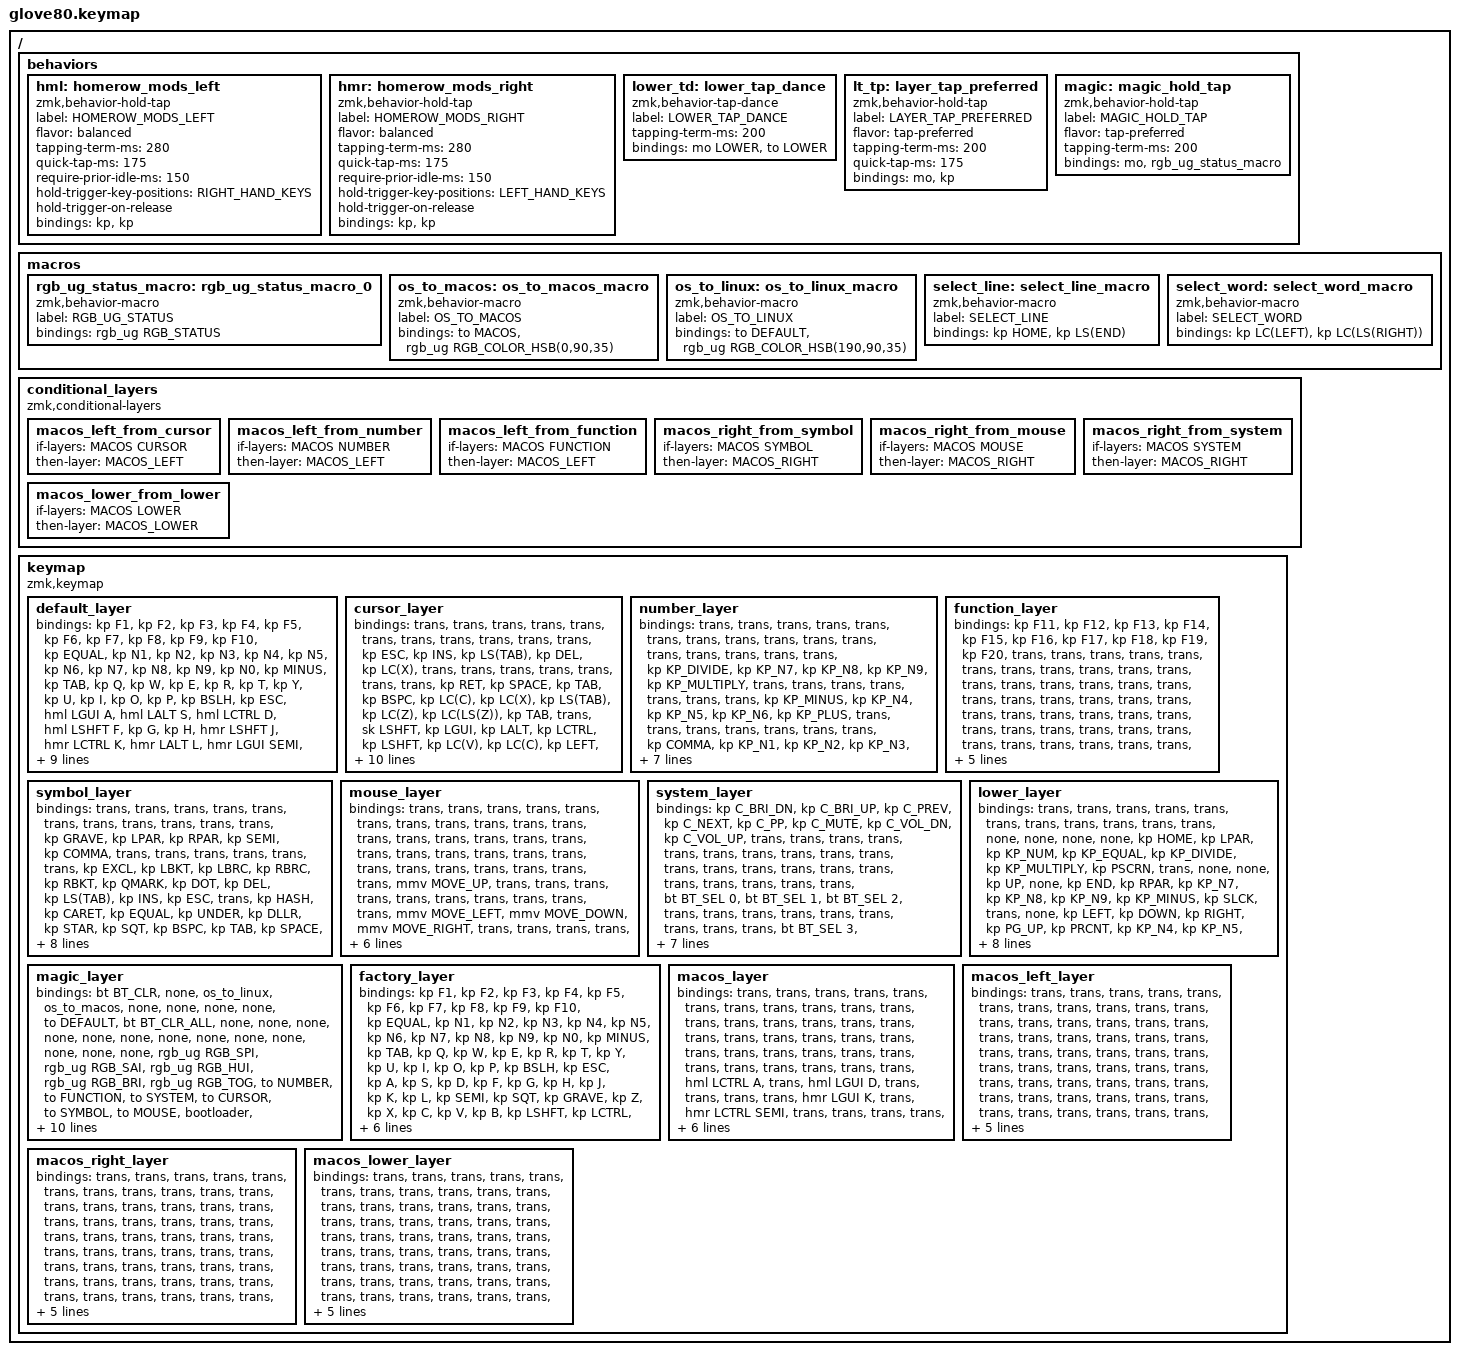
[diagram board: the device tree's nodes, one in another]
/*
 * Dual-OS (macOS / Linux) Glove80 keymap
 *
 * Layout, home-row-mod, and bilateral-combination ideas adapted from
 * sunaku/glove80-keymaps (https://github.com/sunaku/glove80-keymaps).
 * See ../README.md for the full design writeup.
 *
 * Copyright (c) 2020 The ZMK Contributors
 * SPDX-License-Identifier: MIT
 */

#include <behaviors.dtsi>
#include <dt-bindings/zmk/keys.h>
#include <dt-bindings/zmk/bt.h>
#include <dt-bindings/zmk/ext_power.h>
#include <dt-bindings/zmk/outputs.h>
#include <dt-bindings/zmk/rgb.h>
#include <dt-bindings/zmk/pointing.h>

#define HYPER LC(LS(LG(LALT)))

// ---------------------------------------------------------------------------
// Layers
// ---------------------------------------------------------------------------
#define DEFAULT      0
#define CURSOR       1
#define NUMBER       2
#define FUNCTION     3
#define SYMBOL       4
#define MOUSE        5
#define SYSTEM       6
#define LOWER        7
#define MAGIC        8
#define FACTORY      9
#define MACOS        10
#define MACOS_LEFT   11
#define MACOS_RIGHT  12
#define MACOS_LOWER  13

// ---------------------------------------------------------------------------
// Bilateral-combination key-position groups.
//
// Glove80 numbers its 80 key positions 0-79 in physical row-major order (see
// README.md "Bilateral combinations" for the full diagram). LEFT_HAND_KEYS /
// RIGHT_HAND_KEYS list every position that physically belongs to that hand
// (including its own thumb keys). Home-row-mod hold-taps use the *opposite*
// hand's list as `hold-trigger-key-positions`, so a mod only resolves as a
// HOLD when the very next key pressed is on the other hand -- same-hand fast
// typing always resolves as a plain TAP instead of misfiring a modifier.
// ---------------------------------------------------------------------------
#define LEFT_HAND_KEYS \
     0  1  2  3  4 10 11 12 13 14 15 22 23 24 25 26 27 34 35 36 37 38 39 \
    46 47 48 49 50 51 52 53 54 64 65 66 67 68 69 70 71

#define RIGHT_HAND_KEYS \
     5  6  7  8  9 16 17 18 19 20 21 28 29 30 31 32 33 40 41 42 43 44 45 \
    55 56 57 58 59 60 61 62 63 72 73 74 75 76 77 78 79

/ {
    behaviors {
        // Bilateral-combination home row mods. GACS order (pinky->index):
        // GUI, ALT, CTRL, SHIFT. See macOS overlay below for the OS-specific
        // pinky<->middle (GUI<->CTRL) swap.
        hml: homerow_mods_left {
            compatible = "zmk,behavior-hold-tap";
            label = "HOMEROW_MODS_LEFT";
            #binding-cells = <2>;
            flavor = "balanced";
            tapping-term-ms = <280>;
            quick-tap-ms = <175>;
            require-prior-idle-ms = <150>;
            hold-trigger-key-positions = <RIGHT_HAND_KEYS>;
            hold-trigger-on-release;
            bindings = <&kp>, <&kp>;
        };

        hmr: homerow_mods_right {
            compatible = "zmk,behavior-hold-tap";
            label = "HOMEROW_MODS_RIGHT";
            #binding-cells = <2>;
            flavor = "balanced";
            tapping-term-ms = <280>;
            quick-tap-ms = <175>;
            require-prior-idle-ms = <150>;
            hold-trigger-key-positions = <LEFT_HAND_KEYS>;
            hold-trigger-on-release;
            bindings = <&kp>, <&kp>;
        };

        // Tap = momentary Lower, double-tap = stay on Lower until tapped again.
        lower_td: lower_tap_dance {
            compatible = "zmk,behavior-tap-dance";
            label = "LOWER_TAP_DANCE";
            #binding-cells = <0>;
            tapping-term-ms = <200>;
            bindings = <&mo LOWER>, <&to LOWER>;
        };

        // TailorKey-style layer-tap: tap = the key's normal keycode, hold =
        // a layer. "tap-preferred" resolves as a tap the instant another key
        // is pressed, so fast typing/rolling through Space/Backspace/Enter
        // never misfires a layer -- only a deliberate solo hold does. This
        // is how TailorKey (https://sites.google.com/view/tailorkey/moergo/glove80)
        // reaches Symbol/Cursor/Mouse: hold Space/Backspace/Enter instead of
        // spending dedicated thumb keys on them.
        lt_tp: layer_tap_preferred {
            compatible = "zmk,behavior-hold-tap";
            label = "LAYER_TAP_PREFERRED";
            #binding-cells = <2>;
            flavor = "tap-preferred";
            tapping-term-ms = <200>;
            quick-tap-ms = <175>;
            bindings = <&mo>, <&kp>;
        };

        // Hold = momentary Magic layer, tap = show RGB/battery status (stock MoErgo behavior).
        magic: magic_hold_tap {
            compatible = "zmk,behavior-hold-tap";
            label = "MAGIC_HOLD_TAP";
            #binding-cells = <2>;
            flavor = "tap-preferred";
            tapping-term-ms = <200>;
            bindings = <&mo>, <&rgb_ug_status_macro>;
        };
    };

    macros {
        rgb_ug_status_macro: rgb_ug_status_macro_0 {
            label = "RGB_UG_STATUS";
            compatible = "zmk,behavior-macro";
            #binding-cells = <0>;
            bindings = <&rgb_ug RGB_STATUS>;
        };

        // OS-mode select. Each key unconditionally sets the OS overlay layer
        // state AND recolors the underglow, so the two keys behave like a
        // radio button (not a toggle) and the RGB always matches the mode.
        os_to_macos: os_to_macos_macro {
            label = "OS_TO_MACOS";
            compatible = "zmk,behavior-macro";
            #binding-cells = <0>;
            bindings
                = <&to MACOS>,
                  <&rgb_ug RGB_COLOR_HSB(0,90,35)>;
        };

        os_to_linux: os_to_linux_macro {
            label = "OS_TO_LINUX";
            compatible = "zmk,behavior-macro";
            #binding-cells = <0>;
            bindings
                = <&to DEFAULT>,
                  <&rgb_ug RGB_COLOR_HSB(190,90,35)>;
        };

        // Select from line start to line end -- ZMK has no built-in
        // "select line", Sunaku's Cursor layer expects one.
        select_line: select_line_macro {
            label = "SELECT_LINE";
            compatible = "zmk,behavior-macro";
            #binding-cells = <0>;
            bindings = <&kp HOME>, <&kp LS(END)>;
        };

        // Jump to the start of the current word, then select to its end --
        // Sunaku's Cursor layer's "select word".
        select_word: select_word_macro {
            label = "SELECT_WORD";
            compatible = "zmk,behavior-macro";
            #binding-cells = <0>;
            bindings = <&kp LC(LEFT)>, <&kp LC(LS(RIGHT))>;
        };
    };

    // ZMK cannot detect the connected host's OS -- there is no such signal
    // over USB/BLE. The MACOS layer above is a persistent overlay toggled
    // explicitly by the os_to_macos/os_to_linux keys on the Magic layer.
    // conditional-layers combines it with whichever functional layer (Cursor/
    // Number/Function on the left, Symbol/Mouse/System on the right, or
    // Lower) is currently held, activating the matching *_left/_right/_lower
    // overlay so Mac-specific bindings on those layers take effect too.
    conditional_layers {
        compatible = "zmk,conditional-layers";
        macos_left_from_cursor   { if-layers = <MACOS CURSOR>;   then-layer = <MACOS_LEFT>; };
        macos_left_from_number   { if-layers = <MACOS NUMBER>;   then-layer = <MACOS_LEFT>; };
        macos_left_from_function { if-layers = <MACOS FUNCTION>; then-layer = <MACOS_LEFT>; };
        macos_right_from_symbol  { if-layers = <MACOS SYMBOL>;   then-layer = <MACOS_RIGHT>; };
        macos_right_from_mouse   { if-layers = <MACOS MOUSE>;    then-layer = <MACOS_RIGHT>; };
        macos_right_from_system  { if-layers = <MACOS SYSTEM>;   then-layer = <MACOS_RIGHT>; };
        macos_lower_from_lower   { if-layers = <MACOS LOWER>;    then-layer = <MACOS_LOWER>; };
    };

    keymap {
        compatible = "zmk,keymap";

        // -----------------------------------------------------------------------------------------------------------------------------
        // |  F1   |  F2 |  F3 |  F4  |  F5  |                                                               |  F6   |  F7   |  F8  |   F9  |  F10 |
        // |  =    |  1  |  2  |  3   |  4   |  5   |                                                 |  6   |   7   |   8   |  9   |   0   |   -  |
        // |  TAB  |  Q  |  W  |  E   |  R   |  T   |                                                 |  Y   |   U   |   I   |  O   |   P   |   \  |
        // |  ESC  | GUI/A|ALT/S|CTRL/D|SHFT/F|  G   |                                                 |  H   |SHFT/J |CTRL/K |ALT/L |GUI/;  |   '  |
        // |   `   |  Z  |  X  |  C   |  V   |  B   |NUMBER |CAPSWORD|LOWERtd| |CAPS  |  --  |SYSTEM |  N   |   M   |   ,   |  .   |   /   | PGUP |
        // |MAGIC/RGB|HOME| END | LEFT|RIGHT |      |BSPC/CURSOR|DEL|FUNCTION| |MAGIC |RET/MOUSE|SPACE/SYMBOL| |  UP   | DOWN  |  [   |   ]   | PGDN |
        //
        // TailorKey-style layer access: Cursor/Mouse/Symbol have no dedicated
        // thumb key -- hold Backspace/Enter/Space instead (see lt_tp above).
        // That frees three thumb keys for Caps Word and Caps Lock (`--` is a
        // spare, currently &none).
        default_layer {
            bindings = <
        &kp F1       &kp F2       &kp F3      &kp F4      &kp F5                                                                          &kp F6  &kp F7      &kp F8      &kp F9      &kp F10
        &kp EQUAL    &kp N1       &kp N2      &kp N3      &kp N4      &kp N5                                                        &kp N6  &kp N7  &kp N8      &kp N9      &kp N0      &kp MINUS
        &kp TAB      &kp Q        &kp W       &kp E       &kp R       &kp T                                                         &kp Y   &kp U   &kp I       &kp O       &kp P       &kp BSLH
        &kp ESC      &hml LGUI A  &hml LALT S &hml LCTRL D &hml LSHFT F &kp G                                                        &kp H   &hmr LSHFT J &hmr LCTRL K &hmr LALT L &hmr LGUI SEMI &kp SQT
        &kp GRAVE    &kp Z        &kp X       &kp C       &kp V       &kp B    &mo NUMBER &caps_word &lower_td   &kp CAPS &none &mo SYSTEM  &kp N   &kp M   &kp COMMA   &kp DOT     &kp FSLH    &kp PG_UP
        &magic MAGIC 0 &kp HOME   &kp END     &kp LEFT    &kp RIGHT           &lt_tp CURSOR BSPC   &kp DEL    &mo FUNCTION &mo MAGIC &lt_tp MOUSE RET   &lt_tp SYMBOL SPACE           &kp UP  &kp DOWN    &kp LBKT    &kp RBKT    &kp PG_DN
            >;
        };

        // Sunaku's actual Cursor layer (https://sunaku.github.io/moergo-glove80-keyboard.html#cursor-layer),
        // which TailorKey's own Cursor layer is explicitly built on -- same
        // physical row/column mapping approach as Symbol above. Cut/Copy/
        // Paste/Undo/Redo/Find are plain Ctrl-chords here (portable across
        // OSes); see macos_right_layer below for the one Mac-specific
        // override Sunaku's diagram calls for (Home/End -> Cmd+Left/Right).
        // Left thumb cluster stays &trans -- Sunaku's own left thumb is idle
        // there too (his Cursor activation is a dedicated left-hand key,
        // same physical role as our held Backspace, and he leaves the rest
        // of that cluster grey). Right thumb cluster gets his selection
        // shortcuts (Extend word/line, Select none/word/line/all) since his
        // diagram populates all six positions there, including the one that
        // doubles as this file's secondary `&mo MAGIC` key -- fine here
        // since the primary Magic key (bottom-left corner, held via
        // `&magic`) stays &trans and reachable throughout. One Sunaku cell
        // (left R6/outermost, "Search bar") was dropped rather than
        // overriding *that* Magic key.
        cursor_layer {
            bindings = <
        &trans       &trans       &trans       &trans       &trans       &trans       &trans       &trans       &trans       &trans
        &trans       &kp ESC      &kp INS      &kp LS(TAB)  &kp DEL      &kp LC(X)                                                    &trans       &trans       &trans       &trans       &trans       &trans
        &trans       &kp RET      &kp SPACE    &kp TAB      &kp BSPC     &kp LC(C)                                                    &kp LC(X)    &kp LS(TAB)  &kp LC(Z)    &kp LC(LS(Z)) &kp TAB     &trans
        &sk LSHFT    &kp LGUI     &kp LALT     &kp LCTRL    &kp LSHFT    &kp LC(V)                                                    &kp LC(C)    &kp LEFT     &kp UP       &kp DOWN     &kp RIGHT    &sk RSHFT
        &kp LC(L)    &kp LC(A)    &select_line &select_word &kp LC(F)   &trans        &trans       &trans       &trans       &kp RIGHT    &kp LS(END)  &kp LC(LS(RIGHT)) &kp LC(V) &kp HOME     &kp PG_UP    &kp PG_DN    &kp END      &kp LC(L)
        &trans       &kp LC(Z)    &kp LC(LS(Z)) &kp LS(F3)  &kp F3                   &trans       &trans       &trans       &kp LC(A)    &select_line &select_word              &kp LC(F)    &kp LS(F3)   &kp F3       &kp LC(H)    &kp LC(K)
            >;
        };

        number_layer {
            bindings = <
        &trans       &trans       &trans       &trans       &trans       &trans       &trans       &trans       &trans       &trans
        &trans       &trans       &trans       &trans       &trans       &trans       &kp KP_DIVIDE &kp KP_N7   &kp KP_N8    &kp KP_N9    &kp KP_MULTIPLY &trans
        &trans       &trans       &trans       &trans       &trans       &trans       &kp KP_MINUS &kp KP_N4    &kp KP_N5    &kp KP_N6    &kp KP_PLUS  &trans
        &trans       &trans       &trans       &trans       &trans       &trans       &kp COMMA    &kp KP_N1    &kp KP_N2    &kp KP_N3    &kp KP_EQUAL &trans
        &trans       &trans       &trans       &trans       &trans       &trans       &trans       &trans       &trans       &trans       &trans       &trans       &kp DOT      &kp KP_N0    &kp KP_N0    &kp KP_DOT   &kp KP_ENTER &trans
        &trans       &trans       &trans       &trans       &trans       &trans       &trans       &trans       &trans       &trans       &trans       &trans       &trans       &trans       &trans       &trans
            >;
        };

        function_layer {
            bindings = <
        &kp F11      &kp F12      &kp F13      &kp F14      &kp F15      &kp F16      &kp F17      &kp F18      &kp F19      &kp F20
        &trans       &trans       &trans       &trans       &trans       &trans       &trans       &trans       &trans       &trans       &trans       &trans
        &trans       &trans       &trans       &trans       &trans       &trans       &trans       &trans       &trans       &trans       &trans       &trans
        &trans       &trans       &trans       &trans       &trans       &trans       &trans       &trans       &trans       &trans       &trans       &trans
        &trans       &trans       &trans       &trans       &trans       &trans       &trans       &trans       &trans       &trans       &trans       &trans       &trans       &trans       &trans       &trans       &trans       &trans
        &trans       &trans       &trans       &trans       &trans       &trans       &trans       &trans       &trans       &trans       &trans       &trans       &trans       &trans       &trans       &trans
            >;
        };

        // Sunaku's actual Symbol layer (https://sunaku.github.io/moergo-glove80-keyboard.html#symbol-layer),
        // which TailorKey's own Symbol layer is explicitly built on. Mapped
        // by physical row/column onto this file's layout, not by borrowed
        // semantics -- e.g. row4 is wherever the home row lives here, not
        // "wherever Sunaku's A/S/D/F happen to sit". Right-hand row3/row4
        // also carry Sunaku's "spacegram" fix: Space itself is busy being
        // held to reach this layer, so Space/Backspace/Tab/Enter/Del/Insert
        // get plain-tap duplicates on the home row so you don't have to let
        // go of Space to use them. Left thumb cluster gets Sunaku's extra
        // symbols too (| . * % : @) -- his Symbol activation is a dedicated
        // key, same as ours (Space), so his left thumb is just as idle as
        // ours while Symbol is held, and he repurposes it. Right thumb
        // cluster stays &trans (Sunaku's diagram leaves his idle too, aside
        // from the activation key itself).
        // Two Sunaku cells were dropped as ambiguous rather than guessed at:
        // a two-dot glyph (left R6/outermost) and a triple-grave glyph
        // (right R4/outermost, both currently &trans / pass-through).
        symbol_layer {
            bindings = <
        &trans       &trans       &trans       &trans       &trans       &trans       &trans       &trans       &trans       &trans
        &trans       &kp GRAVE    &kp LPAR     &kp RPAR     &kp SEMI     &kp COMMA                                                    &trans       &trans       &trans       &trans       &trans       &trans
        &kp EXCL     &kp LBKT     &kp LBRC     &kp RBRC     &kp RBKT     &kp QMARK                                                    &kp DOT      &kp DEL      &kp LS(TAB)  &kp INS      &kp ESC      &trans
        &kp HASH     &kp CARET    &kp EQUAL    &kp UNDER    &kp DLLR     &kp STAR                                                     &kp SQT      &kp BSPC     &kp TAB      &kp SPACE    &kp RET      &trans
        &kp TILDE    &kp LT       &kp PIPE     &kp MINUS    &kp GT       &kp FSLH     &kp PIPE     &kp DOT      &kp STAR     &trans       &trans       &trans       &kp SEMI     &kp DQT      &kp SQT      &kp GRAVE    &kp BSLH     &sk RSHFT
        &trans       &kp AMPS     &kp SQT      &kp DQT      &kp PLUS                 &kp PRCNT    &kp COLON    &kp AT       &trans       &trans       &trans                    &kp LSHFT    &kp LCTRL    &kp LALT     &kp LGUI     &trans
            >;
        };

        mouse_layer {
            bindings = <
        &trans       &trans       &trans       &trans       &trans       &trans       &trans       &trans       &trans       &trans
        &trans       &trans       &trans       &trans       &trans       &trans       &trans       &trans       &trans       &trans       &trans       &trans
        &trans       &trans       &trans       &trans       &trans       &trans       &trans       &trans       &mmv MOVE_UP &trans       &trans       &trans
        &trans       &trans       &trans       &trans       &trans       &trans       &trans       &mmv MOVE_LEFT &mmv MOVE_DOWN &mmv MOVE_RIGHT &trans &trans
        &trans       &trans       &trans       &trans       &trans       &trans       &trans       &trans       &trans       &mkp LCLK    &mkp MCLK    &mkp RCLK    &msc SCRL_UP &trans       &trans       &trans       &trans       &trans
        &trans       &trans       &trans       &trans       &trans       &trans       &trans       &trans       &trans       &trans       &trans       &msc SCRL_DOWN &trans     &trans       &trans       &trans
            >;
        };

        system_layer {
            bindings = <
        &kp C_BRI_DN &kp C_BRI_UP &kp C_PREV   &kp C_NEXT   &kp C_PP     &kp C_MUTE   &kp C_VOL_DN &kp C_VOL_UP &trans       &trans
        &trans       &trans       &trans       &trans       &trans       &trans       &trans       &trans       &trans       &trans       &trans       &trans
        &trans       &trans       &trans       &trans       &trans       &trans       &trans       &bt BT_SEL 0 &bt BT_SEL 1 &bt BT_SEL 2 &trans       &trans
        &trans       &trans       &trans       &trans       &trans       &trans       &trans       &bt BT_SEL 3 &bt BT_SEL 4 &out OUT_USB &trans       &trans
        &trans       &trans       &trans       &trans       &trans       &trans       &trans       &trans       &trans       &trans       &trans       &trans       &trans       &out OUT_BLE &out OUT_TOG &trans       &trans       &trans
        &trans       &trans       &trans       &trans       &trans       &trans       &trans       &trans       &trans       &trans       &trans       &trans       &trans       &trans       &trans       &trans
            >;
        };

        lower_layer {
            bindings = <
        &trans       &trans       &trans       &trans       &trans       &trans       &trans       &trans       &trans       &trans
        &trans       &none        &none        &none        &none        &kp HOME     &kp LPAR     &kp KP_NUM   &kp KP_EQUAL &kp KP_DIVIDE &kp KP_MULTIPLY &kp PSCRN
        &trans       &none        &none        &kp UP       &none        &kp END      &kp RPAR     &kp KP_N7    &kp KP_N8    &kp KP_N9    &kp KP_MINUS &kp SLCK
        &trans       &none        &kp LEFT     &kp DOWN     &kp RIGHT    &kp PG_UP    &kp PRCNT    &kp KP_N4    &kp KP_N5    &kp KP_N6    &kp KP_PLUS  &none
        &trans       &kp K_CMENU  &none        &kp F11      &kp F12      &kp PG_DN    &trans       &trans       &to DEFAULT  &trans       &trans       &trans       &kp COMMA    &kp KP_N1    &kp KP_N2    &kp KP_N3    &kp KP_ENTER &trans
        &trans       &kp CAPS     &kp INS      &kp F11      &kp F12                   &trans       &trans       &trans       &trans       &trans       &trans                    &kp KP_N0    &kp KP_N0    &kp KP_DOT   &kp KP_ENTER &trans
            >;
        };

        // Right side of row 3 is a TailorKey-style "layer switcher" row:
        // hold Magic, tap one of these to jump straight to (and persist on)
        // a layer that would otherwise need a hold -- handy for Cursor/
        // Symbol/Mouse now that they live on held Backspace/Space/Enter
        // instead of a dedicated thumb key. `&to X` a second time (or
        // `&to DEFAULT`/the layer's own escape) is how you leave again.
        magic_layer {
            bindings = <
        &bt BT_CLR   &none        &os_to_linux &os_to_macos &none                                                                          &none        &none        &none        &to DEFAULT  &bt BT_CLR_ALL
        &none        &none        &none        &none        &none        &none                                                       &none        &none        &none        &none        &none        &none
        &none        &rgb_ug RGB_SPI &rgb_ug RGB_SAI &rgb_ug RGB_HUI &rgb_ug RGB_BRI &rgb_ug RGB_TOG                                    &to NUMBER   &to FUNCTION &to SYSTEM   &to CURSOR   &to SYMBOL   &to MOUSE
        &bootloader  &rgb_ug RGB_SPD &rgb_ug RGB_SAD &rgb_ug RGB_HUD &rgb_ug RGB_BRD &rgb_ug RGB_EFF                                    &none        &none        &none        &none        &none        &bootloader
        &sys_reset   &none        &none        &none        &none        &none        &bt BT_SEL 2 &bt BT_SEL 3 &to FACTORY  &none        &none        &none        &none        &none        &none        &none        &none        &sys_reset
        &none        &none        &none        &none        &none                    &bt BT_SEL 0 &bt BT_SEL 1 &out OUT_USB &none        &none        &none                     &none        &none        &none        &none        &to FACTORY
            >;
        };

        // Escape hatch: plain QWERTY, no home-row mods, no custom layers.
        // Reachable from Magic (bottom-right key); its own Lower-position
        // key (&to DEFAULT) is the only way back, in case something else
        // misbehaves.
        factory_layer {
            bindings = <
        &kp F1       &kp F2       &kp F3      &kp F4      &kp F5                                                                          &kp F6  &kp F7      &kp F8      &kp F9      &kp F10
        &kp EQUAL    &kp N1       &kp N2      &kp N3      &kp N4      &kp N5                                                        &kp N6  &kp N7  &kp N8      &kp N9      &kp N0      &kp MINUS
        &kp TAB      &kp Q        &kp W       &kp E       &kp R       &kp T                                                         &kp Y   &kp U   &kp I       &kp O       &kp P       &kp BSLH
        &kp ESC      &kp A        &kp S       &kp D       &kp F       &kp G                                                         &kp H   &kp J   &kp K       &kp L       &kp SEMI    &kp SQT
        &kp GRAVE    &kp Z        &kp X       &kp C       &kp V       &kp B    &kp LSHFT  &kp LCTRL  &to DEFAULT  &kp LGUI   &kp RCTRL &kp RSHFT   &kp N   &kp M   &kp COMMA   &kp DOT     &kp FSLH    &kp PG_UP
        &none        &kp HOME     &kp END     &kp LEFT    &kp RIGHT           &kp BSPC   &kp DEL    &kp LALT     &kp RALT  &kp RET   &kp SPACE           &kp UP  &kp DOWN    &kp LBKT    &kp RBKT    &kp PG_DN
            >;
        };

        // macOS overlay: mostly transparent. Swaps the pinky<->middle
        // finger mods (GUI<->CTRL) and remaps Home/End to Cmd+Left/Right,
        // matching sunaku's OPERATING_SYSTEM == 'M' behavior -- but applied
        // at runtime via &to MACOS / &to DEFAULT instead of a rebuild.
        macos_layer {
            bindings = <
        &trans       &trans       &trans       &trans       &trans       &trans       &trans       &trans       &trans       &trans
        &trans       &trans       &trans       &trans       &trans       &trans       &trans       &trans       &trans       &trans       &trans       &trans
        &trans       &trans       &trans       &trans       &trans       &trans       &trans       &trans       &trans       &trans       &trans       &trans
        &trans       &hml LCTRL A &trans       &hml LGUI D  &trans       &trans       &trans       &trans       &hmr LGUI K  &trans       &hmr LCTRL SEMI &trans
        &trans       &trans       &trans       &trans       &trans       &trans       &trans       &trans       &trans       &trans       &trans       &trans       &trans       &trans       &trans       &trans       &trans       &trans
        &trans       &kp LG(LEFT) &kp LG(RIGHT) &trans      &trans                    &trans       &trans       &trans       &trans       &trans       &trans                    &trans       &trans       &trans       &trans       &trans
            >;
        };

        macos_left_layer {
            bindings = <
        &trans       &trans       &trans       &trans       &trans       &trans       &trans       &trans       &trans       &trans
        &trans       &trans       &trans       &trans       &trans       &trans       &trans       &trans       &trans       &trans       &trans       &trans
        &trans       &trans       &trans       &trans       &trans       &trans       &trans       &trans       &trans       &trans       &trans       &trans
        &trans       &trans       &trans       &trans       &trans       &trans       &trans       &trans       &trans       &trans       &trans       &trans
        &trans       &trans       &trans       &trans       &trans       &trans       &trans       &trans       &trans       &trans       &trans       &trans       &trans       &trans       &trans       &trans       &trans       &trans
        &trans       &trans       &trans       &trans       &trans       &trans       &trans       &trans       &trans       &trans       &trans       &trans       &trans       &trans       &trans       &trans
            >;
        };

        // Cursor layer's Home/End (R_C2R5/R_C5R5) become Cmd+Left/Right under
        // macOS, matching Sunaku's Cursor-layer diagram, which hardcodes
        // this -- our own dual-OS design keeps the base cursor_layer OS-
        // portable (plain Home/End) and applies the Mac-only swap here.
        macos_right_layer {
            bindings = <
        &trans       &trans       &trans       &trans       &trans       &trans       &trans       &trans       &trans       &trans
        &trans       &trans       &trans       &trans       &trans       &trans       &trans       &trans       &trans       &trans       &trans       &trans
        &trans       &trans       &trans       &trans       &trans       &trans       &trans       &trans       &trans       &trans       &trans       &trans
        &trans       &trans       &trans       &trans       &trans       &trans       &trans       &trans       &trans       &trans       &trans       &trans
        &trans       &trans       &trans       &trans       &trans       &trans       &trans       &trans       &trans       &trans       &trans       &trans       &trans       &kp LG(LEFT) &trans       &trans       &kp LG(RIGHT) &trans
        &trans       &trans       &trans       &trans       &trans       &trans       &trans       &trans       &trans       &trans       &trans       &trans       &trans       &trans       &trans       &trans
            >;
        };

        macos_lower_layer {
            bindings = <
        &trans       &trans       &trans       &trans       &trans       &trans       &trans       &trans       &trans       &trans
        &trans       &trans       &trans       &trans       &trans       &trans       &trans       &trans       &trans       &trans       &trans       &trans
        &trans       &trans       &trans       &trans       &trans       &trans       &trans       &trans       &trans       &trans       &trans       &trans
        &trans       &trans       &trans       &trans       &trans       &trans       &trans       &trans       &trans       &trans       &trans       &trans
        &trans       &trans       &trans       &trans       &trans       &trans       &trans       &trans       &trans       &trans       &trans       &trans       &trans       &trans       &trans       &trans       &trans       &trans
        &trans       &trans       &trans       &trans       &trans       &trans       &trans       &trans       &trans       &trans       &trans       &trans       &trans       &trans       &trans       &trans
            >;
        };
    };
};
